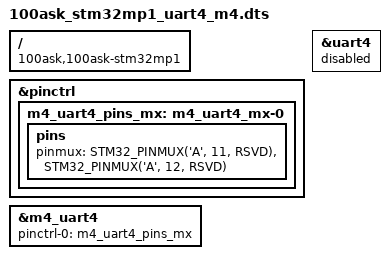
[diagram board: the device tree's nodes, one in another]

/*
 * Device tree overlay for usart4
 */

#include "dt-bindings/gpio/gpio.h"
#include "dt-bindings/pinctrl/stm32-pinfunc.h"

/dts-v1/;
/plugin/;

/ {
     compatible = "100ask,100ask-stm32mp1", "st,stm32mp157";
    fragment@0 {
        target = <&pinctrl>;
        __overlay__ {
			m4_uart4_pins_mx: m4_uart4_mx-0 {
				pins {
					pinmux = <STM32_PINMUX('A', 11, RSVD)>, /* UART4_RX */
							 <STM32_PINMUX('A', 12, RSVD)>; /* UART4_TX */
				};
			};
        };
    };
	
    fragment@1 {
        target = <&uart4>;
        __overlay__ {
			status = "disable";
        };
    };
	
		fragment@2 {
        target = <&m4_uart4>;
        __overlay__ {
			pinctrl-names = "default";
			pinctrl-0 = <&m4_uart4_pins_mx>;
			status = "okay";
        };
    };
};

